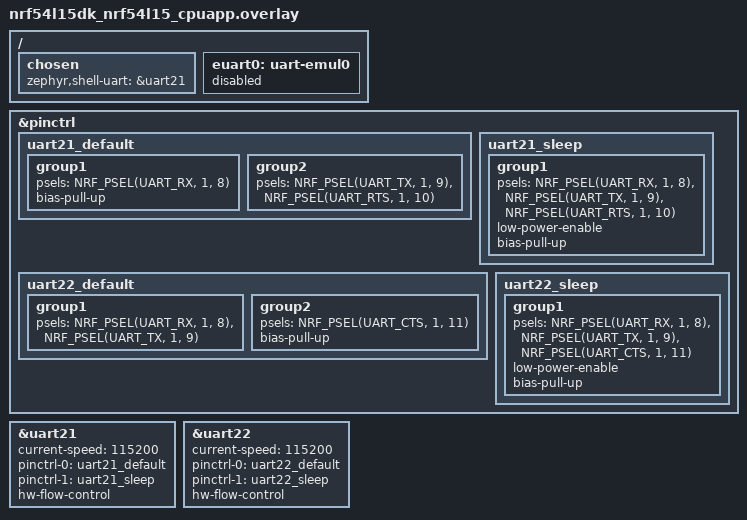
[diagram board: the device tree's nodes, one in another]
/*
 * Copyright (c) 2025 Nordic Semiconductor ASA
 *
 * SPDX-License-Identifier: Apache-2.0
 */

/ {
	chosen {
		zephyr,shell-uart = &uart21;
	};

	euart0: uart-emul0 {
		status = "disabled";
	};
};

&pinctrl {
	uart21_default: uart21_default {
		group1 {
			psels = <NRF_PSEL(UART_RX, 1, 8)>;
			bias-pull-up;
		};

		group2 {
			psels = <NRF_PSEL(UART_TX, 1, 9)>,
				<NRF_PSEL(UART_RTS, 1, 10)>;
		};
	};

	uart21_sleep: uart21_sleep {
		group1 {
			psels = <NRF_PSEL(UART_RX, 1, 8)>,
				<NRF_PSEL(UART_TX, 1, 9)>,
				<NRF_PSEL(UART_RTS, 1, 10)>;
			low-power-enable;
			bias-pull-up;
		};
	};

	uart22_default: uart22_default {
		group1 {
			psels = <NRF_PSEL(UART_RX, 1, 8)>,
				<NRF_PSEL(UART_TX, 1, 9)>;
		};

		group2 {
			psels = <NRF_PSEL(UART_CTS, 1, 11)>;
			bias-pull-up;
		};
	};

	uart22_sleep: uart22_sleep {
		group1 {
			psels = <NRF_PSEL(UART_RX, 1, 8)>,
				<NRF_PSEL(UART_TX, 1, 9)>,
				<NRF_PSEL(UART_CTS, 1, 11)>;
			low-power-enable;
			bias-pull-up;
		};
	};
};

shell_uart: &uart21 {
	status = "okay";
	current-speed = <115200>;
	pinctrl-0 = <&uart21_default>;
	pinctrl-1 = <&uart21_sleep>;
	pinctrl-names = "default", "sleep";
	hw-flow-control;
};

aux_uart: &uart22 {
	status = "okay";
	current-speed = <115200>;
	pinctrl-0 = <&uart22_default>;
	pinctrl-1 = <&uart22_sleep>;
	pinctrl-names = "default", "sleep";
	hw-flow-control;
};
